# STM32U3B5 register map
File version: 1.0
CPU: CM33 r0p1, little endian, MPU, FPU, 4 interrupt priority bits
Registers are 32-bit, read-write, reset 0x0 unless marked. A register's access mark holds for its fields unless they carry their own. Offsets are from the block's base; [hi:lo] are bit positions; {n}, {i} and the like mark numbered series; 'fields as' and 'values as' point back to an identical list.

## RCC (part 2 of 2) — RCC register block
Base 0x40030C00
Same registers: SEC_RCC 0x50030C00
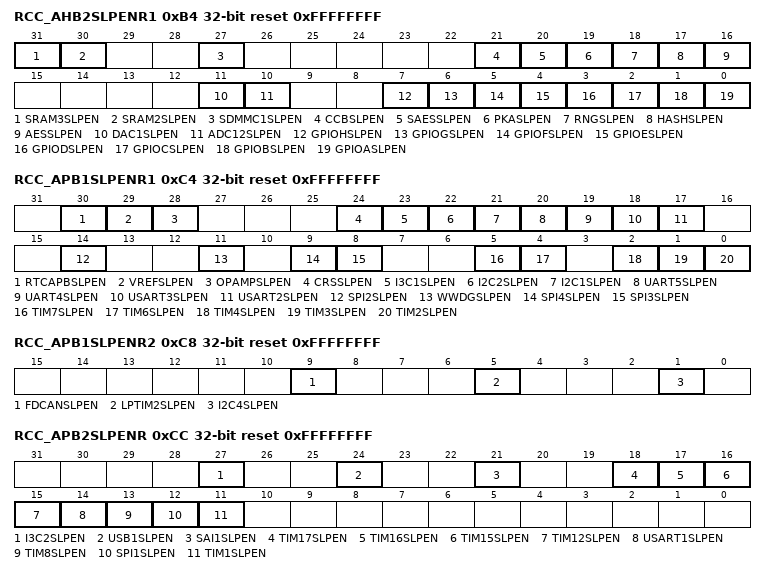
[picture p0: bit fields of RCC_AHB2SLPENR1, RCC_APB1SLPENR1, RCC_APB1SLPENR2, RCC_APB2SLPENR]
0xB4 RCC_AHB2SLPENR1 reset 0xFFFFFFFF — RCC AHB2 peripheral clock enable in Sleep mode register 1
  [31] SRAM3SLPEN — SRAM3 clock enable during Sleep mode
    0=SRAM3 clock disabled by the clock gating during Sleep mode; 1=SRAM3 clock enabled by the clock gating during Sleep mode
  [30] SRAM2SLPEN — SRAM2 clock enable during Sleep mode
    0=SRAM2 clock disabled by the clock gating during Sleep mode; 1=SRAM2 clock enabled by the clock gating during Sleep mode
  [27] SDMMC1SLPEN — SDMMC1 clock enable during Sleep mode
    0=SDMMC1 clock disabled by the clock gating during Sleep mode; 1=SDMMC1 clock enabled by the clock gating during Sleep mode
  [21] CCBSLPEN — CCB accelerator clock enable during Sleep mode
    0=CCB clock disabled by the clock gating during Sleep mode; 1=CCB clock enabled by the clock gating during Sleep mode
  [20] SAESSLPEN — SAES accelerator clock enable during Sleep mode
    0=SAES clock disabled by the clock gating during Sleep mode; 1=SAES clock enabled by the clock gating during Sleep mode
  [19] PKASLPEN — PKA clock enable during Sleep mode
    0=PKA clock disabled by the clock gating during Sleep mode; 1=PKA clock enabled by the clock gating during Sleep mode
  [18] RNGSLPEN — RNG clock enable during Sleep mode
    0=RNG clock disabled by the clock gating during Sleep mode; 1=RNG clock enabled by the clock gating during Sleep mode
  [17] HASHSLPEN — HASH clock enable during Sleep mode
    0=HASH clock disabled by the clock gating during Sleep mode; 1=HASH clock enabled by the clock gating during Sleep mode
  [16] AESSLPEN — AES clock enable during Sleep mode
    0=AES clock disabled by the clock gating during Sleep mode; 1=AES clock enabled by the clock gating during Sleep mode
  [11] DAC1SLPEN — DAC1 clock enable during Sleep mode
    0=DAC1 clock disabled by the clock gating during Sleep mode; 1=DAC1 clock enabled by the clock gating during Sleep mode
  [10] ADC12SLPEN — ADC12 clock enable during Sleep mode
    0=ADC12 clock disabled by the clock gating during Sleep mode; 1=ADC12 clock enabled by the clock gating during Sleep mode
  [7] GPIOHSLPEN — I/O port i clock enable during Sleep mode (i = A to H)
    0=I/O port i clock disabled by the clock gating during Sleep mode; 1=I/O port i clock enabled by the clock gating during Sleep mode
  [6] GPIOGSLPEN — I/O port i clock enable during Sleep mode (i = A to H)
    values as GPIOHSLPEN
  [5] GPIOFSLPEN — I/O port i clock enable during Sleep mode (i = A to H)
    values as GPIOHSLPEN
  [4] GPIOESLPEN — I/O port i clock enable during Sleep mode (i = A to H)
    values as GPIOHSLPEN
  [3] GPIODSLPEN — I/O port i clock enable during Sleep mode (i = A to H)
    values as GPIOHSLPEN
  [2] GPIOCSLPEN — I/O port i clock enable during Sleep mode (i = A to H)
    values as GPIOHSLPEN
  [1] GPIOBSLPEN — I/O port i clock enable during Sleep mode (i = A to H)
    values as GPIOHSLPEN
  [0] GPIOASLPEN — I/O port i clock enable during Sleep mode (i = A to H)
    values as GPIOHSLPEN
0xB8 RCC_AHB2SLPENR2 reset 0xFFFFFFFF — RCC AHB2 peripheral clock enable in Sleep mode register 2
  [4] OCTOSPI1SLPEN — OCTOSPI1 clock enable during Sleep mode
    0=OCTOSPI1 clock disabled by the clock gating during Sleep mode; 1=OCTOSPI1 clock enabled by the clock gating during Sleep mode
0xBC RCC_AHB1SLPENR2 reset 0xFFFFFFFF — RCC AHB1 peripheral clock enable in Sleep mode register 2
  [2] PWRSLPEN — PWR clock enable during Sleep mode
    0=PWR clock disabled by the clock gating during Sleep mode; 1=PWR clock enabled by the clock gating during Sleep mode
0xC4 RCC_APB1SLPENR1 reset 0xFFFFFFFF — RCC APB1 peripheral clock enable in Sleep mode register 1
  [30] RTCAPBSLPEN — RTC and TAMP APB clock enable during Sleep mode
    0=RTC and TAMP APB clock disabled by the clock gating during Sleep mode; 1=RTC and TAMP APB clock enabled by the clock gating during Sleep mode
  [29] VREFSLPEN — VREFBUF clock enable during Sleep mode
    0=VREFBUF clock disabled by the clock gating during Sleep mode; 1=VREFBUF clock enabled by the clock gating during Sleep mode
  [28] OPAMPSLPEN — OPAMP clock enable during Sleep mode
    0=OPAMP clock disabled by the clock gating during Sleep mode; 1=OPAMP clock enabled by the clock gating during Sleep mode
  [24] CRSSLPEN — CRS clock enable during Sleep mode
    0=CRS clock disabled by the clock gating during Sleep mode; 1=CRS clock enabled by the clock gating during Sleep mode
  [23] I3C1SLPEN — I3C1 clock enable during Sleep mode
    0=I3C1 clock disabled by the clock gating during Sleep mode; 1=I3C1 clock enabled by the clock gating during Sleep mode
  [22] I2C2SLPEN — I2C2 clock enable during Sleep mode
    0=I2C2 clock disabled by the clock gating during Sleep mode; 1=I2C2 clock enabled by the clock gating during Sleep mode
  [21] I2C1SLPEN — I2C1 clock enable during Sleep mode
    0=I2C1 clock disabled by the clock gating during Sleep mode; 1=I2C1 clock enabled by the clock gating during Sleep mode
  [20] UART5SLPEN — UART5 clock enable during Sleep mode
    0=UART5 clock disabled by the clock gating during Sleep mode; 1=UART5 clock enabled by the clock gating during Sleep mode
  [19] UART4SLPEN — UART4 clock enable during Sleep mode
    0=UART4 clock disabled by the clock gating during Sleep mode; 1=UART4 clock enabled by the clock gating during Sleep mode
  [18] USART3SLPEN — USART3 clock enable during Sleep mode
    0=USART3 clock disabled by the clock gating during Sleep mode; 1=USART3 clock enabled by the clock gating during Sleep mode
  [17] USART2SLPEN — USART2 clock enable during Sleep mode
    0=USART2 clock disabled by the clock gating during Sleep mode; 1=USART2 clock enabled by the clock gating during Sleep mode
  [14] SPI2SLPEN — SPI2 clock enable during Sleep mode
    0=SPI2 clock disabled by the clock gating during Sleep mode; 1=SPI2 clock enabled by the clock gating during Sleep mode
  [11] WWDGSLPEN — WWDG clock enable during Sleep mode
    0=WWDG clock disabled by the clock gating during Sleep mode; 1=WWDG clock enabled by the clock gating during Sleep mode
  [9] SPI4SLPEN — SPI4 clock enable during Sleep mode
    0=SPI4 clock disabled by the clock gating during Sleep mode; 1=SPI4 clock enabled by the clock gating during Sleep mode
  [8] SPI3SLPEN — SPI3 clock enable during Sleep mode
    0=SPI3 clock disabled by the clock gating during Sleep mode; 1=SPI3 clock enabled by the clock gating during Sleep mode
  [5] TIM7SLPEN — TIMj clock enable during Sleep mode
    0=TIMj clock disabled by the clock gating during Sleep mode; 1=TIMj clock enabled by the clock gating during Sleep mode
  [4] TIM6SLPEN — TIMj clock enable during Sleep mode
    values as TIM7SLPEN
  [2] TIM4SLPEN — TIMj clock enable during Sleep mode
    values as TIM7SLPEN
  [1] TIM3SLPEN — TIMj clock enable during Sleep mode
    values as TIM7SLPEN
  [0] TIM2SLPEN — TIMj clock enable during Sleep mode
    values as TIM7SLPEN
0xC8 RCC_APB1SLPENR2 reset 0xFFFFFFFF — RCC APB1 peripheral clock enable in Sleep mode register 2
  [9] FDCANSLPEN — FDCAN clock enable during Sleep mode
    0=FDCAN1 and FDCAN2 clock disabled by the clock gating during Sleep mode; 1=FDCAN1 and FDCAN2 clock enabled by the clock gating during Sleep mode
  [5] LPTIM2SLPEN — LPTIM2 clock enable during Sleep mode
    0=LPTIM2 clock disabled by the clock gating during Sleep mode; 1=LPTIM2 clock enabled by the clock gating during Sleep mode
  [1] I2C4SLPEN — I2C4 clock enable during Sleep mode
    0=I2C4 clock disabled by the clock gating during Sleep mode; 1=I2C4 clock enabled by the clock gating during Sleep mode
0xCC RCC_APB2SLPENR reset 0xFFFFFFFF — RCC APB2 peripheral clock enable in Sleep mode register
  [27] I3C2SLPEN — I3C2 clock enable during Sleep mode
    0=I3C2 clock disabled by the clock gating during Sleep mode; 1=I3C2 clock enabled by the clock gating during Sleep mode
  [24] USB1SLPEN — USB1 clock enable during Sleep mode
    0=USB1 clock disabled by the clock gating during Sleep mode; 1=USB1 clock enabled by the clock gating during Sleep mode
  [21] SAI1SLPEN — SAI1 clock enable during Sleep mode
    0=SAI1 clock disabled by the clock gating during Sleep mode; 1=SAI1 clock enabled by the clock gating during Sleep mode
  [18] TIM17SLPEN — TIMi clock enable during Sleep mode
    0=TIMi clock disabled during Sleep mode; 1=TIMi clock enabled during Sleep mode
  [17] TIM16SLPEN — TIMi clock enable during Sleep mode
    values as TIM17SLPEN
  [16] TIM15SLPEN — TIMi clock enable during Sleep mode
    values as TIM17SLPEN
  [15] TIM12SLPEN — TIM12 clock enable during Sleep mode
    0=TIM12 clock disabled during Sleep mode; 1=TIM12 clock enabled during Sleep mode
  [14] USART1SLPEN — USART1clock enable during Sleep mode
    0=USART1clock disabled by the clock gating during Sleep mode; 1=USART1clock enabled by the clock gating during Sleep mode
  [13] TIM8SLPEN — TIM8 clock enable during Sleep mode
    0=TIM8 clock disabled during Sleep mode; 1=TIM8 clock enabled during Sleep mode
  [12] SPI1SLPEN — SPI1 clock enable during Sleep mode
    0=SPI1 clock disabled by the clock gating during Sleep mode; 1=SPI1 clock enabled by the clock gating during Sleep mode
  [11] TIM1SLPEN — TIM1 clock enable during Sleep mode
    0=TIM1 clock disabled during Sleep mode; 1=TIM1 clock enabled during Sleep mode
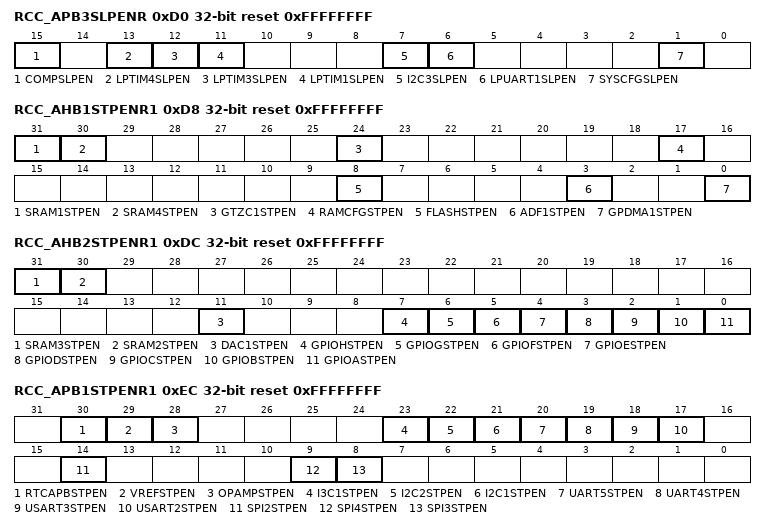
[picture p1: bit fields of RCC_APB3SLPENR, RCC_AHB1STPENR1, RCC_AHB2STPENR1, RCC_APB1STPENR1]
0xD0 RCC_APB3SLPENR reset 0xFFFFFFFF — RCC APB3 peripheral clock enable in Sleep mode register
  [15] COMPSLPEN — COMP clock enable during Sleep mode
    0=COMP clock disabled by the clock gating during Sleep mode; 1=COMP clock enabled by the clock gating during Sleep mode
  [13] LPTIM4SLPEN — LPTIMi clock enable during Sleep mode
    0=LPTIMi clock disabled during Sleep mode; 1=LPTIMi clock enabled during Sleep mode
  [12] LPTIM3SLPEN — LPTIMi clock enable during Sleep mode
    values as LPTIM4SLPEN
  [11] LPTIM1SLPEN — LPTIM1clock enable during Sleep mode
    0=LPTIM1 clock disabled during Sleep mode; 1=LPTIM1 clock enabled during Sleep mode
  [7] I2C3SLPEN — I2C3 clock enable during Sleep mode
    0=I2C3 clock disabled by the clock gating during Sleep mode; 1=I2C3 clock enabled by the clock gating during Sleep mode
  [6] LPUART1SLPEN — LPUART1 clock enable during Sleep mode
    0=LPUART1 clock disabled by the clock gating during Sleep mode; 1=LPUART1 clock enabled by the clock gating during Sleep m
  [1] SYSCFGSLPEN — SYSCFG clock enable during Sleep mode
    0=SYSCFG clock disabled by the clock gating during Sleep mode; 1=SYSCFG clock enabled by the clock gating during Sleep mode
0xD8 RCC_AHB1STPENR1 reset 0xFFFFFFFF — RCC AHB1 peripheral clock enable in Stop mode register
  [31] SRAM1STPEN — SRAM1 clock enable during Stop mode
    0=SRAM1 clock disabled by the clock gating during Stop mode; 1=SRAM1 clock enabled by the clock gating during Stop mode
  [30] SRAM4STPEN — SRAM4 clock enable during Stop mode
    0=SRAM4 clock disabled by the clock gating during Stop mode; 1=SRAM4 clock enabled by the clock gating during Stop mode
  [24] GTZC1STPEN — GTZC1 clock enable during Stop mode
    0=GTZC1 clock disabled by the clock gating during Stop mode; 1=GTZC1 clock enabled by the clock gating during Stop mode
  [17] RAMCFGSTPEN — RAMCFG clock enable during Stop mode
    0=RAMCFG clock disabled by the clock gating during Stop mode; 1=RAMCFG clock enabled by the clock gating during Stop mode
  [8] FLASHSTPEN — FLASH clock enable during Stop mode
    0=FLASH clock disabled by the clock gating during Stop mode; 1=FLASH clock enabled by the clock gating during Stop mode
  [3] ADF1STPEN — ADF1 clock enable during Stop mode.
    0=ADF1 clock disabled by the clock gating during Stop mode; 1=ADF1 clock enabled by the clock gating during Stop mode
  [0] GPDMA1STPEN — GPDMA1 clock enable during Stop mode.
    0=GPDMA1 clock disabled by the clock gating during Stop mode; 1=GPDMA1 clock enabled by the clock gating during Stop mode
0xDC RCC_AHB2STPENR1 reset 0xFFFFFFFF — RCC AHB2 peripheral clock enable in Stop mode register 1
  [31] SRAM3STPEN — SRAM3 clock enable during Stop mode
    0=SRAM3 clock disabled by the clock gating during Stop mode; 1=SRAM3 clock enabled by the clock gating during Stop mode
  [30] SRAM2STPEN — SRAM2 clock enable during Stop mode
    0=SRAM2 clock disabled by the clock gating during Stop mode; 1=SRAM2 clock enabled by the clock gating during Stop mode
  [11] DAC1STPEN — DAC1 clock enable during Stop mode
    0=DAC1 clock disabled by the clock gating during Stop mode; 1=DAC1 clock enabled by the clock gating during Stop mode
  [7] GPIOHSTPEN — I/O port i clock enable during Stop mode (i = H to A)
    0=I/O port i clock disabled by the clock gating during Stop mode; 1=I/O port i clock enabled by the clock gating during Stop mode
  [6] GPIOGSTPEN — I/O port i clock enable during Stop mode (i = H to A)
    values as GPIOHSTPEN
  [5] GPIOFSTPEN — I/O port i clock enable during Stop mode (i = H to A)
    values as GPIOHSTPEN
  [4] GPIOESTPEN — I/O port i clock enable during Stop mode (i = H to A)
    values as GPIOHSTPEN
  [3] GPIODSTPEN — I/O port i clock enable during Stop mode (i = H to A)
    values as GPIOHSTPEN
  [2] GPIOCSTPEN — I/O port i clock enable during Stop mode (i = H to A)
    values as GPIOHSTPEN
  [1] GPIOBSTPEN — I/O port i clock enable during Stop mode (i = H to A)
    values as GPIOHSTPEN
  [0] GPIOASTPEN — I/O port i clock enable during Stop mode (i = H to A)
    values as GPIOHSTPEN
0xEC RCC_APB1STPENR1 reset 0xFFFFFFFF — RCC APB1 peripheral clock enable in Stop mode register 1
  [30] RTCAPBSTPEN — RTC and TAMP APB clock enable during Stop mode
    0=RTC and TAMP APB clock disabled by the clock gating during Stop mode; 1=RTC and TAMP APB clock enabled by the clock gating during Stop mode
  [29] VREFSTPEN — VREFBUF clock enable during Stop mode
    0=VREFBUF clock disabled by the clock gating during Stop mode; 1=VREFBUF clock enabled by the clock gating during Stop mode
  [28] OPAMPSTPEN — OPAMP clock enable during Stop mode
    0=OPAMP clock disabled by the clock gating during Stop mode; 1=OPAMP clock enabled by the clock gating during Stop mode
  [23] I3C1STPEN — I3C1 clock enable during Stop mode
    0=I3C1 clock disabled by the clock gating during Stop mode; 1=I3C1 clock enabled by the clock gating during Stop mode
  [22] I2C2STPEN — I2C2 clock enable during Stop mode
    0=I2C2 clock disabled by the clock gating during Stop mode; 1=I2C2 clock enabled by the clock gating during Stop mode
  [21] I2C1STPEN — I2C1 clock enable during Stop mode
    0=I2C1 clock disabled by the clock gating during Stop mode; 1=I2C1 clock enabled by the clock gating during Stop mode
  [20] UART5STPEN — UART5 clock enable during Stop mode
    0=UART5 clock disabled by the clock gating during Stop mode; 1=UART5 clock enabled by the clock gating during Stop mode
  [19] UART4STPEN — UART4 clock enable during Stop mode
    0=UART4 clock disabled by the clock gating during Stop mode; 1=UART4 clock enabled by the clock gating during Stop mode
  [18] USART3STPEN — USART3 clock enable during Stop mode
    0=USART3 clock disabled by the clock gating during Stop mode; 1=USART3 clock enabled by the clock gating during Stop mode
  [17] USART2STPEN — USART2 clock enable during Stop mode
    0=USART2 clock disabled by the clock gating during Stop mode; 1=USART2 clock enabled by the clock gating during Stop mode
  [14] SPI2STPEN — SPI2 clock enable during Stop mode
    0=SPI2 clock disabled by the clock gating during Stop mode; 1=SPI2 clock enabled by the clock gating during Stop mode
  [9] SPI4STPEN — SPI4 clock enable during Stop mode
    0=SPI4 clock disabled by the clock gating during Stop mode; 1=SPI4 clock enabled by the clock gating during Stop mode
  [8] SPI3STPEN — SPI3 clock enable during Stop mode
    0=SPI3 clock disabled by the clock gating during Stop mode; 1=SPI3 clock enabled by the clock gating during Stop mode
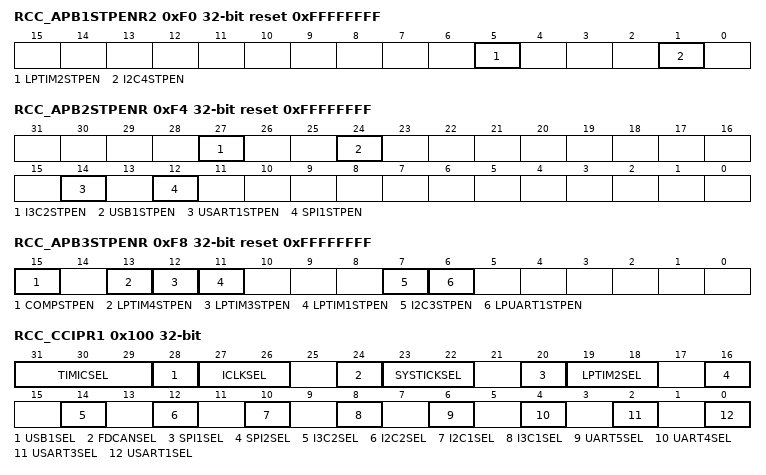
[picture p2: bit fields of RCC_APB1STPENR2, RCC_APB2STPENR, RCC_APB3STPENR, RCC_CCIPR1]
0xF0 RCC_APB1STPENR2 reset 0xFFFFFFFF — RCC APB1 peripheral clock enable in Stop mode register 2
  [5] LPTIM2STPEN — LPTIM2 clock enable during Stop mode
    0=LPTIM2 clock disabled by the clock gating during Stop mode; 1=LPTIM2 clock enabled by the clock gating during Stop mode
  [1] I2C4STPEN — I2C4 clock enable during Stop mode
    0=I2C4 clock disabled by the clock gating during Stop mode; 1=I2C4 clock enabled by the clock gating during Stop mode
0xF4 RCC_APB2STPENR reset 0xFFFFFFFF — RCC APB2 peripheral clock enable in Stop mode register
  [27] I3C2STPEN — I3C2 clock enable during Stop mode
    0=I3C2 clock disabled by the clock gating during Stop mode; 1=I3C2 clock enabled by the clock gating during Stop mode
  [24] USB1STPEN — USB1 clock enable during Stop mode
    0=USB1 clock disabled by the clock gating during Stop mode; 1=USB1 clock enabled by the clock gating during Stop mode
  [14] USART1STPEN — USART1clock enable during Stop mode
    0=USART1 clock disabled by the clock gating during Stop mode; 1=USART1 clock enabled by the clock gating during Stop mode
  [12] SPI1STPEN — SPI1 clock enable during Stop mode
    0=SPI1 clock disabled by the clock gating during Stop mode; 1=SPI1 clock enabled by the clock gating during Stop mode
0xF8 RCC_APB3STPENR reset 0xFFFFFFFF — RCC APB3 peripheral clock enable in Stop mode register
  [15] COMPSTPEN — COMP clock enable during Stop mode
    0=COMP clock disabled by the clock gating during Stop mode; 1=COMP clock enabled by the clock gating during Stop mode
  [13] LPTIM4STPEN — LPTIMi clock enable during Stop mode
    0=LPTIMi clock disabled during Stop mode; 1=LPTIMi clock enabled during Stop mode
  [12] LPTIM3STPEN — LPTIMi clock enable during Stop mode
    values as LPTIM4STPEN
  [11] LPTIM1STPEN — LPTIM1clock enable during Stop mode
    0=LPTIM1 clock disabled during Stop mode; 1=LPTIM1 clock enabled during Stop mode
  [7] I2C3STPEN — I2C3 clock enable during Stop mode
    0=I2C3 clock disabled by the clock gating during Stop mode; 1=I2C3 clock enabled by the clock gating during Stop mode
  [6] LPUART1STPEN — LPUART1 clock enable during Stop mode
    0=LPUART1 clock disabled by the clock gating during Stop mode; 1=LPUART1 clock enabled by the clock gating during Stop m
0x100 RCC_CCIPR1 — RCC peripheral independent clock configuration register 1
  [31:29] TIMICSEL — Clock sources for TIM16,TIM17, and LPTIM2 internal input capture
    {v}=HSI, MSIK and MSIS dividers disabled (v=0..3); 4=HSI/256, MSIS/1024 and MSIS/4 are generated and can be selected by TIM16, TIM17, and LPTIM2 as internal input capture; 5=HSI/256, MSIS/1024 and MSIK/4 are generated and can be selected by TIM16, TIM17, and LPTIM2 as internal input capture; 6=HSI/256, MSIK/1024 and MSIS/4 are generated and can be selected by TIM16, TIM17, and LPTIM2 as internal input capture; 7=HSI/256, MSIK/1024 and MSIK/4 are generated and can be selected by TIM16, TIM17, and LPTIM2 as internal input capture
  [28] USB1SEL — USB1 kernel clock prescaler selection
    0=usbsdmmc_iclk selected; 1=usbsdmmc_iclk/2 selected
  [27:26] ICLKSEL — Intermediate clock source selection
    0=HSI48 selected; 1=MSIK selected; 2=HSE selected; 3=SYSCLK selected
  [24] FDCANSEL — FDCAN1 and FDCAN2 kernel clock source selection
    0=SYSCLK selected; 1=MSIK selected
  [23:22] SYSTICKSEL — SysTick clock source selection
    0=HCLK/8 selected; 1=LSI selected; 2=LSE selected
  [20] SPI1SEL — SPI1 kernel clock source selection
    0=PCLK2 selected; 1=MSIK selected
  [19:18] LPTIM2SEL — Low-power timer 2 kernel clock source selection
    0=PCLK1 selected; 1=LSI selected; 2=HSI16 selected; 3=LSE selected
  [16] SPI2SEL — SPI2 kernel clock source selection
    0=PCLK1 selected; 1=MSIK selected
  [14] I3C2SEL — I3C2 kernel clock source selection
    0=PCLK2 selected; 1=MSIK selected
  [12] I2C2SEL — I2C2 kernel clock source selection
    0=PCLK1 selected; 1=MSIK selected
  [10] I2C1SEL — I2C1 kernel clock source selection
    0=PCLK1 selected; 1=MSIK selected
  [8] I3C1SEL — I3C1 kernel clock source selection
    0=PCLK1 selected; 1=MSIK selected
  [6] UART5SEL — UART5 kernel clock source selection
    0=PCLK1 selected; 1=HSI16 selected
  [4] UART4SEL — UART4 kernel clock source selection
    0=PCLK1 selected; 1=HSI16 selected
  [2] USART3SEL — USART3 kernel clock source selection
    0=PCLK1 selected; 1=HSI16 selected
  [0] USART1SEL — USART1 kernel clock source selection
    0=PCLK2 selected; 1=HSI16 selected
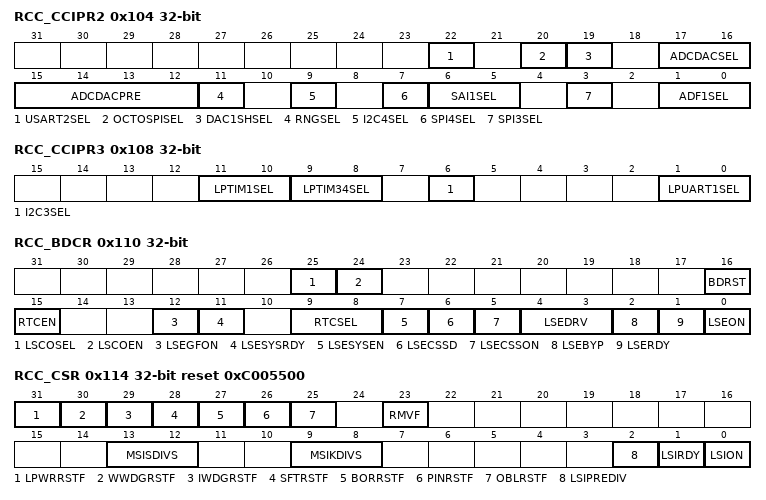
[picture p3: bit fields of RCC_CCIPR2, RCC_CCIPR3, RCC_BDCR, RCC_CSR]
0x104 RCC_CCIPR2 — RCC peripheral independent clock configuration register 2
  [22] USART2SEL — USART2 kernel clock source selection
    0=PCLK1 selected; 1=HSI16 selected
  [20] OCTOSPISEL — OCTOSPI1 kernel clock source selection
    0=SYSCLK selected; 1=MSIK selected
  [19] DAC1SHSEL — DAC1 sample and hold clock source selection
    0=LSE selected; 1=LSI selected
  [17:16] ADCDACSEL — ADC12 and DAC1 intermediate kernel clock source selection
    0=HCLK selected; 1=HSE selected; 2=MSIK selected
  [15:12] ADCDACPRE — ADC12 and DAC1 kernel clock prescaler
    0=adcdac_iclk; {v}=adcdac_iclk/2 (v=1..7); 8=adcdac_iclk/4; 9=adcdac_iclk/8; 10=adcdac_iclk/16; 11=adcdac_iclk/32; 12=adcdac_iclk/64; 13=adcdac_iclk/128; 14=adcdac_iclk/256; 15=adcdac_iclk/512
  [11] RNGSEL — RNG kernel clock source selection
    0=HSI48 selected; 1=MSIK selected
  [9] I2C4SEL — I2C4 kernel clock source selection
    0=PCLK1 selected; 1=MSIK selected
  [7] SPI4SEL — SPI4 kernel clock source selection
    0=PCLK1 selected; 1=MSIK selected
  [6:5] SAI1SEL — SAI1 kernel clock source selection
    0=MSIK selected; 1=input pin AUDIOCLK selected; 2=HSE clock selected
  [3] SPI3SEL — SPI3 kernel clock source selection
    0=PCLK1 selected; 1=MSIK selected
  [1:0] ADF1SEL — ADF1 kernel clock source selection
    0=HCLK; 1=Input pin AUDIOCLK selected; 2=MSIK clock selected; 3=SAI1 kernel clock selected
0x108 RCC_CCIPR3 — RCC peripheral independent clock configuration register 3
  [11:10] LPTIM1SEL — LPTIM1 kernel clock source selection
    0=MSIK clock selected; 1=LSI selected; 2=HSI16 selected; 3=LSE selected
  [9:8] LPTIM34SEL — LPTIM3 and LPTIM4 kernel clock source selection
    values as LPTIM1SEL
  [6] I2C3SEL — I2C3 kernel clock source selection
    0=PCLK3 selected; 1=MSIK selected
  [1:0] LPUART1SEL — LPUART1 kernel clock source selection
    0=PCLK3 selected; 1=HSI16 selected; 2=LSE selected; 3=MSIK selected
0x110 RCC_BDCR reset not defined — RCC backup domain control register
  [25] LSCOSEL — Low-speed clock output selection
    0=LSI selected; 1=LSE selected
  [24] LSCOEN — Low-speed clock output (LSCO) enable
    0=LSCO disabled; 1=LSCO enabled
  [16] BDRST — Backup domain software reset
    0=No effect; 1=Reset the entire backup domain
  [15] RTCEN — RTC and TAMP clock enable
    0=RTC and TAMP clock disabled; 1=RTC and TAMP clock enabled
  [12] LSEGFON — LSE clock glitch filter enable
    0=LSE glitch filter disabled; 1=LSE glitch filter enabled
  [11] LSESYSRDY — LSE system clock (LSESYS) ready
    0=LSESYS clock not ready; 1=LSESYS clock ready
  [9:8] RTCSEL — RTC and TAMP clock source selection
    0=No clock selected; 1=LSE selected; 2=LSI selected; 3=HSE/32 selected
  [7] LSESYSEN — LSE system clock (LSESYS) enable
    0=LSE can be used only for RTC, TAMP, and CSS on LSE; 1=LSE can be used by any other peripheral or function
  [6] LSECSSD — CSS on LSE failure detection
    0=No failure detected on LSE; 1=Failure detected on LSE
  [5] LSECSSON — CSS on LSE enable
    0=CSS on LSE OFF; 1=CSS on LSE ON
  [4:3] LSEDRV — LSE oscillator drive capability
    0='Xtal mode' lower driving capability; 1='Xtal mode' medium-low driving capability; 2='Xtal mode' medium-high driving capability; 3='Xtal mode' higher driving capability
  [2] LSEBYP — LSE oscillator bypass
    0=LSE oscillator not bypassed; 1=LSE oscillator bypassed
  [1] LSERDY — LSE oscillator ready
    0=LSE oscillator not ready; 1=LSE oscillator ready
  [0] LSEON — LSE oscillator enable
    0=LSE oscillator OFF; 1=LSE oscillator ON
0x114 RCC_CSR reset 0xC005500 — RCC control/status register
  [31] LPWRRSTF — Low-power reset flag
    0=No illegal low-power mode reset occurred; 1=Illegal low-power mode reset occurred
  [30] WWDGRSTF — Window watchdog reset flag
    0=No window watchdog reset occurred; 1=Window watchdog reset occurred
  [29] IWDGRSTF — Independent watchdog reset flag
    0=No independent watchdog reset occurred; 1=Independent watchdog reset occurred
  [28] SFTRSTF — Software reset flag
    0=No software reset occurred; 1=Software reset occurred
  [27] BORRSTF — BOR flag
    0=No BOR occurred; 1=BOR occurred
  [26] PINRSTF — NRST pin reset flag
    0=No reset from NRST pin occurred; 1=Reset from NRST pin occurred
  [25] OBLRSTF — Option-byte loader reset flag
    0=No reset from option-byte loading occurred; 1=Reset from option-byte loading occurred
  [23] RMVF — Remove reset flag
    0=No effect; 1=Clear the reset flags
  [13:12] MSISDIVS — MSIS oscillator division after Standby mode
    1=Range 5 around 12 MHz (reset value); 2=Range 6 around 6 MHz; 3=Range 7 around 3 MHz
  [9:8] MSIKDIVS — MSIK oscillator division after Standby mode
    values as MSISDIVS
  [2] LSIPREDIV — Low-speed clock divider configuration
    0=LSI not divided; 1=LSI divided by 128
  [1] LSIRDY — LSI oscillator ready
    0=LSI oscillator not ready; 1=LSI oscillator ready
  [0] LSION — LSI oscillator enable
    0=LSI oscillator OFF; 1=LSI oscillator ON
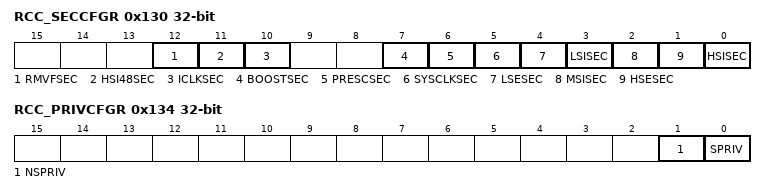
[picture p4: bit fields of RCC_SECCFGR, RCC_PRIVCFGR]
0x130 RCC_SECCFGR — RCC secure configuration register
  [all] fields
    0=Nonsecure; 1=Secure
  [12] RMVFSEC — Remove reset flag security
  [11] HSI48SEC — HSI48 clock configuration and status bit security
  [10] ICLKSEC — Intermediate clock source selection security
  [7] BOOSTSEC — EPOD booster configuration bit security
  [6] PRESCSEC — AHBx/APBx prescaler configuration bit security
  [5] SYSCLKSEC — SYSCLK clock selection, STOPWUCK bit, clock output on MCO configuration security
  [4] LSESEC — LSE clock configuration and status bit security
  [3] LSISEC — LSI clock configuration and status bit security
  [2] MSISEC — MSI clock configuration and status bit security
  [1] HSESEC — HSE clock configuration, status bits, and HSE_CSS security
  [0] HSISEC — HSI clock configuration and status bit security
0x134 RCC_PRIVCFGR — RCC privilege configuration register
  [1] NSPRIV — RCC nonsecure function privilege configuration
    0=Read and write to RCC nonsecure functions can be done by privileged or unprivileged access; 1=Read and write to RCC nonsecure functions can be done by privileged access only
  [0] SPRIV — RCC secure function privilege configuration
    0=Read and write to RCC secure functions can be done by privileged or unprivileged access; 1=Read and write to RCC secure functions can be done by privileged access only
